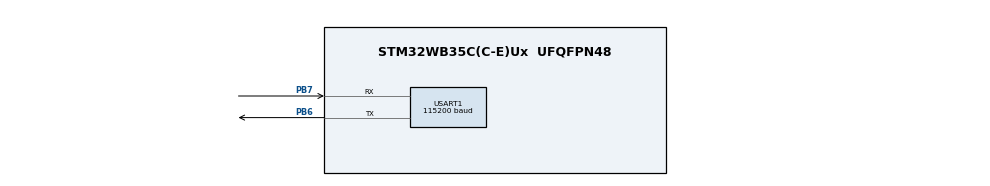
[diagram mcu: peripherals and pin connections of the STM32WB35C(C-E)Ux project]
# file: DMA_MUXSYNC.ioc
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Dma.Request0=USART1_TX
Dma.USART1_TX.0.Direction=DMA_MEMORY_TO_PERIPH
Dma.USART1_TX.0.EventEnable=ENABLE
Dma.USART1_TX.0.Instance=DMA1_Channel1
Dma.USART1_TX.0.MemDataAlignment=DMA_MDATAALIGN_BYTE
Dma.USART1_TX.0.MemInc=DMA_MINC_ENABLE
Dma.USART1_TX.0.Mode=DMA_NORMAL
Dma.USART1_TX.0.PeriphDataAlignment=DMA_PDATAALIGN_BYTE
Dma.USART1_TX.0.PeriphInc=DMA_PINC_DISABLE
Dma.USART1_TX.0.Polarity=HAL_DMAMUX_REQ_GEN_RISING
Dma.USART1_TX.0.Priority=DMA_PRIORITY_LOW
Dma.USART1_TX.0.RequestNumber=1
Dma.USART1_TX.0.SignalID=HAL_DMAMUX1_REQ_GEN_EXTI0
Dma.USART1_TX.0.SyncEnable=ENABLE
Dma.USART1_TX.0.SyncPolarity=HAL_DMAMUX_SYNC_RISING
Dma.USART1_TX.0.SyncRequestNumber=4
Dma.USART1_TX.0.SyncSignalID=HAL_DMAMUX1_SYNC_LPTIM1_OUT
LPTIM1.ClockPrescaler=LPTIM_PRESCALER_DIV4
LPTIM1.TriggerSource=LPTIM_TRIGSOURCE_SOFTWARE
LPTIM1.UpdateMode=LPTIM_UPDATE_ENDOFPERIOD
Mcu.Family=STM32WB
Mcu.Name=STM32WB35C(C-E)Ux
Mcu.Package=UFQFPN48
NVIC.DMA1_Channel1_IRQn=true\:0\:0\:false\:false\:true\:false\:true
NVIC.DMAMUX1_OVR_IRQn=true\:0\:0\:false\:false\:true\:false\:true
NVIC.PriorityGroup=NVIC_PRIORITYGROUP_4
NVIC.USART1_IRQn=true\:0\:0\:false\:false\:true\:true\:true
PB6.GPIO_Speed=GPIO_SPEED_FREQ_VERY_HIGH
PB6.Mode=Asynchronous
PB6.Signal=USART1_TX
PB7.GPIO_Speed=GPIO_SPEED_FREQ_VERY_HIGH
PB7.Mode=Asynchronous
PB7.Signal=USART1_RX
PC14-OSC32_IN.Mode=LSE-External-Oscillator
PC14-OSC32_IN.Signal=RCC_OSC32_IN
PC15-OSC32_OUT.Mode=LSE-External-Oscillator
PC15-OSC32_OUT.Signal=RCC_OSC32_OUT
ProjectManager.HeapSize=0x200
ProjectManager.StackSize=0x400
ProjectManager.TargetToolchain=EWARM V8
RCC.AHB2CLKDivider=RCC_SYSCLK_DIV2
RCC.AHBFreq_Value=64000000
RCC.APB1Freq_Value=64000000
RCC.APB1TimFreq_Value=64000000
RCC.APB2Freq_Value=64000000
RCC.APB2TimFreq_Value=64000000
RCC.APB3Freq_Value=16000000
RCC.CodegenConfigPeriph=true
RCC.CortexFreq_Value=64000000
RCC.EXTERNAL_CLOCK_VALUE=4800000
RCC.HCLKFreq_Value=64000000
RCC.HSE_VALUE=8000000
RCC.HSI48_VALUE=48000000
RCC.HSI_VALUE=16000000
RCC.LPTIM1CLockSelection=RCC_LPTIM1CLKSOURCE_LSE
RCC.PLLN=32
RCC.SYSCLKFreq_VALUE=64000000
RCC.SYSCLKSource=RCC_SYSCLKSOURCE_PLLCLK
RCC.USBFreq_Value=48000000
RCC.VCOOutputFreq_Value=128000000
USART1.AutoBaudRateEnableParam=UART_ADVFEATURE_AUTOBAUDRATE_DISABLE
USART1.BaudRate=115200
USART1.ClockPrescaler=PRESCALER_DIV1
USART1.DMADisableonRxErrorParam=ADVFEATURE_DMA_ENABLEONRXERROR
USART1.DataInvertParam=ADVFEATURE_DATAINV_DISABLE
USART1.FIFOMode=FIFOMODE_DISABLE
USART1.MSBFirstParam=ADVFEATURE_MSBFIRST_DISABLE
USART1.Mode=MODE_TX_RX
USART1.OneBitSampling=UART_ONE_BIT_SAMPLE_DISABLE
USART1.OverSampling=UART_OVERSAMPLING_16
USART1.OverrunDisableParam=ADVFEATURE_OVERRUN_ENABLE
USART1.Parity=PARITY_NONE
USART1.RXFIFOThreshold=RXFIFO_THRESHOLD_1EIGHTHFULL
USART1.RxPinLevelInvertParam=ADVFEATURE_RXINV_DISABLE
USART1.StopBits=STOPBITS_1
USART1.SwapParam=ADVFEATURE_SWAP_DISABLE
USART1.TXFIFOThreshold=TXFIFO_THRESHOLD_1EIGHTHFULL
USART1.TxPinLevelInvertParam=ADVFEATURE_TXINV_DISABLE
USART1.VirtualMode-Asynchronous=VM_ASYNC
USART1.WordLength=WORDLENGTH_8B
VP_LPTIM1_VS_LPTIM_counterModeInternalClock.Mode=Counts__internal_clock_event_00
board=custom

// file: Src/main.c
/* USER CODE BEGIN Header */
/**
  ******************************************************************************
  * @file    DMA/DMAMUX_SYNC/Src/main.c
  * @author  MCD Application Team
  * @brief   This example shows how to use the DMA with the DMAMUX to
  *          synchronize a transfer with LPTIM1 output period using the STM32WBxx HAL API.
  ******************************************************************************
  * @attention
  *
  * <h2><center>&copy; Copyright (c) 2019 STMicroelectronics.
  * All rights reserved.</center></h2>
  *
  * This software component is licensed by ST under BSD 3-Clause license,
  * the "License"; You may not use this file except in compliance with the
  * License. You may obtain a copy of the License at:
  *                        opensource.org/licenses/BSD-3-Clause
  *
  ******************************************************************************
  */
/* USER CODE END Header */

#include "main.h"

LPTIM_HandleTypeDef hlptim1;

UART_HandleTypeDef huart1;
DMA_HandleTypeDef hdma_usart1_tx;

/* USER CODE BEGIN PV */
uint8_t TxSyncMessage[] = "\n\r10\n\r09\n\r08\n\r07\n\r06\n\r05\n\r04\n\r03\n\r02\n\r01\n\r00";
/* Size of Transmission buffer */
#define TX_SYNC_MESSAGE_SIZE               (COUNTOF(TxSyncMessage) - 1)

uint8_t BriefMessage[] = "This example shows how to use the DMA with the DMAMUX to synchronize a transfer with LPTIM1 output signal.\n\rThe USART1 is used in DMA synchronized mode to send a countdown from 10 to 00 with a period of 2sec \n\r\n\rStart countdown :\n\r";
#define BRIEF_MESSAGE_SIZE               (COUNTOF(BriefMessage) - 1)

uint8_t TxEndMessage[] = "\n\r\n\rExample Finished\n\r";
#define TX_END_MESSAGE_SIZE               (COUNTOF(TxEndMessage) - 1)

/* USER CODE END PV */

void SystemClock_Config(void);
static void MX_GPIO_Init(void);
static void MX_DMA_Init(void);
static void MX_LPTIM1_Init(void);
static void MX_USART1_UART_Init(void);

int main(void)
{
  /* USER CODE BEGIN 1 */
  uint32_t periodValue;
  uint32_t pulseValue;

  /* USER CODE END 1 */

  /* MCU Configuration--------------------------------------------------------*/

  /* Reset of all peripherals, Initializes the Flash interface and the Systick. */
  HAL_Init();

  /* Configure the system clock */
  SystemClock_Config();

  /* Initialize all configured peripherals */
  MX_GPIO_Init();
  MX_DMA_Init();
  MX_LPTIM1_Init();
  MX_USART1_UART_Init();
  /* USER CODE BEGIN 2 */

  /*##-1- Configure LED2 and LED3 ##*/
  BSP_LED_Init(LED2);
  BSP_LED_Init(LED3);

   periodValue = (2 * LSE_VALUE)/4;    /* Calculate the Timer  Autoreload value for 2sec period */
   pulseValue  = periodValue/2;        /* Set the Timer  pulse value for 50% duty cycle         */

  /* Start the timer */
  if (HAL_LPTIM_PWM_Start(&hlptim1, periodValue, pulseValue) != HAL_OK)
  {
    Error_Handler();
  }

  /*##Send Brief Message with the UART in Polling mode ######################*/
  /* Start transmission data through "BriefMessage" buffer */
  if(HAL_UART_Transmit(&huart1, (uint8_t*)BriefMessage, BRIEF_MESSAGE_SIZE, HAL_MAX_DELAY )!= HAL_OK)
  {
    /* Transfer error in transmission process */
    Error_Handler();
  }

  /*## Start the synchronized transmission process #####################################*/
  /* Start transmission of the countdown data through "TxSyncMessage" buffer */
  if(HAL_UART_Transmit_DMA(&huart1, (uint8_t*)TxSyncMessage, TX_SYNC_MESSAGE_SIZE)!= HAL_OK)
  {
    /* Transfer error in transmission process */
    Error_Handler();
  }

  /*## Wait for the end of the synchronized transfer ###################################*/
  while (HAL_UART_GetState(&huart1) != HAL_UART_STATE_READY)
  {
  }

  /*## Send example ending  Message with the UART in Polling mode #####################################*/
  /* Start transmission data through "TxEndMessage" buffer */
  if(HAL_UART_Transmit(&huart1, (uint8_t*)TxEndMessage, TX_END_MESSAGE_SIZE, HAL_MAX_DELAY )!= HAL_OK)
  {
    /* Transfer error in transmission process */
    Error_Handler();
  }

  BSP_LED_On(LED2);
  /* USER CODE END 2 */

  /* Infinite loop */
  while (1)
  {

  }
}

void SystemClock_Config(void)
{
  RCC_OscInitTypeDef RCC_OscInitStruct = {0};
  RCC_ClkInitTypeDef RCC_ClkInitStruct = {0};
  RCC_PeriphCLKInitTypeDef PeriphClkInitStruct = {0};

  /** Configure LSE Drive Capability
  */
  HAL_PWR_EnableBkUpAccess();
  __HAL_RCC_LSEDRIVE_CONFIG(RCC_LSEDRIVE_LOW);
  /** Configure the main internal regulator output voltage
  */
  __HAL_PWR_VOLTAGESCALING_CONFIG(PWR_REGULATOR_VOLTAGE_SCALE1);
  /** Initializes the CPU, AHB and APB busses clocks
  */
  RCC_OscInitStruct.OscillatorType = RCC_OSCILLATORTYPE_HSI|RCC_OSCILLATORTYPE_LSE
                              |RCC_OSCILLATORTYPE_MSI;
  RCC_OscInitStruct.LSEState = RCC_LSE_ON;
  RCC_OscInitStruct.HSIState = RCC_HSI_ON;
  RCC_OscInitStruct.MSIState = RCC_MSI_ON;
  RCC_OscInitStruct.HSICalibrationValue = RCC_HSICALIBRATION_DEFAULT;
  RCC_OscInitStruct.MSICalibrationValue = RCC_MSICALIBRATION_DEFAULT;
  RCC_OscInitStruct.MSIClockRange = RCC_MSIRANGE_6;
  RCC_OscInitStruct.PLL.PLLState = RCC_PLL_ON;
  RCC_OscInitStruct.PLL.PLLSource = RCC_PLLSOURCE_MSI;
  RCC_OscInitStruct.PLL.PLLM = RCC_PLLM_DIV1;
  RCC_OscInitStruct.PLL.PLLN = 32;
  RCC_OscInitStruct.PLL.PLLP = RCC_PLLP_DIV2;
  RCC_OscInitStruct.PLL.PLLR = RCC_PLLR_DIV2;
  RCC_OscInitStruct.PLL.PLLQ = RCC_PLLQ_DIV2;
  if (HAL_RCC_OscConfig(&RCC_OscInitStruct) != HAL_OK)
  {
    Error_Handler();
  }
  /** Configure the SYSCLKSource, HCLK, PCLK1 and PCLK2 clocks dividers
  */
  RCC_ClkInitStruct.ClockType = RCC_CLOCKTYPE_HCLK4|RCC_CLOCKTYPE_HCLK2
                              |RCC_CLOCKTYPE_HCLK|RCC_CLOCKTYPE_SYSCLK
                              |RCC_CLOCKTYPE_PCLK1|RCC_CLOCKTYPE_PCLK2;
  RCC_ClkInitStruct.SYSCLKSource = RCC_SYSCLKSOURCE_PLLCLK;
  RCC_ClkInitStruct.AHBCLKDivider = RCC_SYSCLK_DIV1;
  RCC_ClkInitStruct.APB1CLKDivider = RCC_HCLK_DIV1;
  RCC_ClkInitStruct.APB2CLKDivider = RCC_HCLK_DIV1;
  RCC_ClkInitStruct.AHBCLK2Divider = RCC_SYSCLK_DIV2;
  RCC_ClkInitStruct.AHBCLK4Divider = RCC_SYSCLK_DIV1;

  if (HAL_RCC_ClockConfig(&RCC_ClkInitStruct, FLASH_LATENCY_3) != HAL_OK)
  {
    Error_Handler();
  }
  /** Initializes the peripherals clocks
  */
  PeriphClkInitStruct.PeriphClockSelection = RCC_PERIPHCLK_SMPS|RCC_PERIPHCLK_USART1
                              |RCC_PERIPHCLK_LPTIM1;
  PeriphClkInitStruct.Usart1ClockSelection = RCC_USART1CLKSOURCE_PCLK2;
  PeriphClkInitStruct.Lptim1ClockSelection = RCC_LPTIM1CLKSOURCE_LSE;
  PeriphClkInitStruct.SmpsClockSelection = RCC_SMPSCLKSOURCE_HSI;
  PeriphClkInitStruct.SmpsDivSelection = RCC_SMPSCLKDIV_RANGE1;
  if (HAL_RCCEx_PeriphCLKConfig(&PeriphClkInitStruct) != HAL_OK)
  {
    Error_Handler();
  }
}

static void MX_LPTIM1_Init(void)
{

  hlptim1.Instance = LPTIM1;
  hlptim1.Init.Clock.Source = LPTIM_CLOCKSOURCE_APBCLOCK_LPOSC;
  hlptim1.Init.Clock.Prescaler = LPTIM_PRESCALER_DIV4;
  hlptim1.Init.Trigger.Source = LPTIM_TRIGSOURCE_SOFTWARE;
  hlptim1.Init.OutputPolarity = LPTIM_OUTPUTPOLARITY_HIGH;
  hlptim1.Init.UpdateMode = LPTIM_UPDATE_ENDOFPERIOD;
  hlptim1.Init.CounterSource = LPTIM_COUNTERSOURCE_INTERNAL;
  hlptim1.Init.Input1Source = LPTIM_INPUT1SOURCE_GPIO;
  hlptim1.Init.Input2Source = LPTIM_INPUT2SOURCE_GPIO;
  if (HAL_LPTIM_Init(&hlptim1) != HAL_OK)
  {
    Error_Handler();
  }

}

static void MX_USART1_UART_Init(void)
{

  huart1.Instance = USART1;
  huart1.Init.BaudRate = 115200;
  huart1.Init.WordLength = UART_WORDLENGTH_8B;
  huart1.Init.StopBits = UART_STOPBITS_1;
  huart1.Init.Parity = UART_PARITY_NONE;
  huart1.Init.Mode = UART_MODE_TX_RX;
  huart1.Init.HwFlowCtl = UART_HWCONTROL_NONE;
  huart1.Init.OverSampling = UART_OVERSAMPLING_16;
  huart1.Init.OneBitSampling = UART_ONE_BIT_SAMPLE_DISABLE;
  huart1.Init.ClockPrescaler = UART_PRESCALER_DIV1;
  huart1.AdvancedInit.AdvFeatureInit = UART_ADVFEATURE_NO_INIT;
  if (HAL_UART_Init(&huart1) != HAL_OK)
  {
    Error_Handler();
  }
  if (HAL_UARTEx_SetTxFifoThreshold(&huart1, UART_TXFIFO_THRESHOLD_1_8) != HAL_OK)
  {
    Error_Handler();
  }
  if (HAL_UARTEx_SetRxFifoThreshold(&huart1, UART_RXFIFO_THRESHOLD_1_8) != HAL_OK)
  {
    Error_Handler();
  }
  if (HAL_UARTEx_DisableFifoMode(&huart1) != HAL_OK)
  {
    Error_Handler();
  }

}

static void MX_DMA_Init(void)
{

  /* DMA controller clock enable */
  __HAL_RCC_DMAMUX1_CLK_ENABLE();
  __HAL_RCC_DMA1_CLK_ENABLE();

  /* DMA interrupt init */
  /* DMA1_Channel1_IRQn interrupt configuration */
  HAL_NVIC_SetPriority(DMA1_Channel1_IRQn, 0, 0);
  HAL_NVIC_EnableIRQ(DMA1_Channel1_IRQn);
  /* DMAMUX1_OVR_IRQn interrupt configuration */
  HAL_NVIC_SetPriority(DMAMUX1_OVR_IRQn, 0, 0);
  HAL_NVIC_EnableIRQ(DMAMUX1_OVR_IRQn);

}

static void MX_GPIO_Init(void)
{

  /* GPIO Ports Clock Enable */
  __HAL_RCC_GPIOC_CLK_ENABLE();
  __HAL_RCC_GPIOB_CLK_ENABLE();

}

void Error_Handler(void)
{
  /* USER CODE BEGIN Error_Handler_Debug */

  /* Turn LED3 on */
  BSP_LED_On(LED3);

  while(1)
  {
  }
  /* USER CODE END Error_Handler_Debug */
}

/************************ (C) COPYRIGHT STMicroelectronics *****END OF FILE****/
